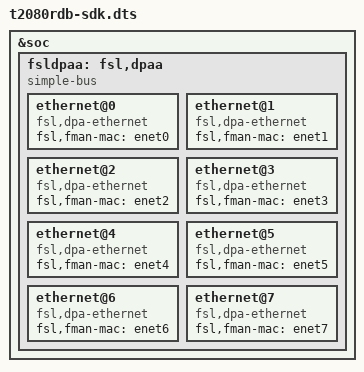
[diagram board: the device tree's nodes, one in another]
#include "t2080rdb.dts"

/include/ "qoriq-fman3-0-sdk.dtsi"
/include/ "qoriq-bman-portals-sdk.dtsi"
/include/ "qoriq-qman3-portals-sdk.dtsi"

&soc {
	fsldpaa: fsl,dpaa {
		compatible = "simple-bus", "fsl,dpaa";
		ethernet@0 {
			compatible = "fsl,dpa-ethernet";
			fsl,fman-mac = <&enet0>;
		};
		ethernet@1 {
			compatible = "fsl,dpa-ethernet";
			fsl,fman-mac = <&enet1>;
		};
		ethernet@2 {
			compatible = "fsl,dpa-ethernet";
			fsl,fman-mac = <&enet2>;
		};
		ethernet@3 {
			compatible = "fsl,dpa-ethernet";
			fsl,fman-mac = <&enet3>;
		};
		ethernet@4 {
			compatible = "fsl,dpa-ethernet";
			fsl,fman-mac = <&enet4>;
		};
		ethernet@5 {
			compatible = "fsl,dpa-ethernet";
			fsl,fman-mac = <&enet5>;
		};
		ethernet@6 {
			compatible = "fsl,dpa-ethernet";
			fsl,fman-mac = <&enet6>;
		};
		ethernet@7 {
			compatible = "fsl,dpa-ethernet";
			fsl,fman-mac = <&enet7>;
		};
	};
};
